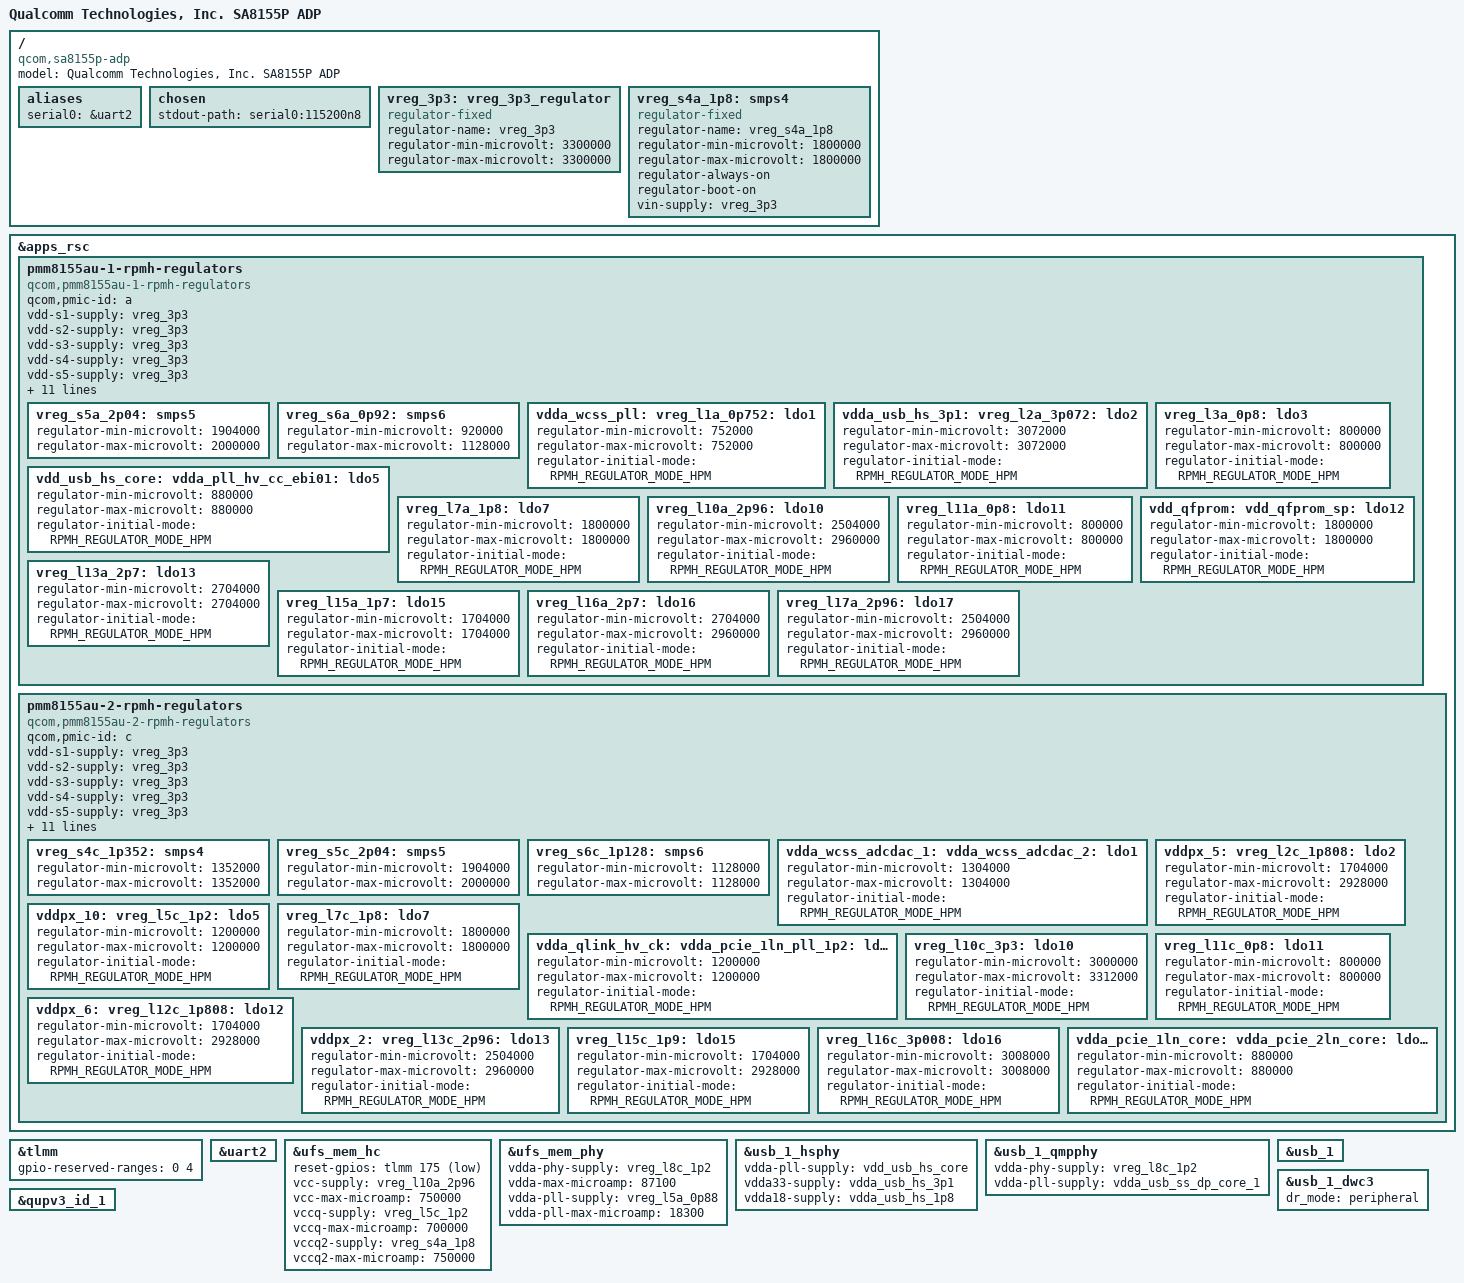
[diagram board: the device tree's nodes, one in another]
// SPDX-License-Identifier: BSD-3-Clause
/*
 * Copyright (c) 2021, Linaro Limited
 */

/dts-v1/;

#include <dt-bindings/regulator/qcom,rpmh-regulator.h>
#include <dt-bindings/gpio/gpio.h>
#include "sm8150.dtsi"
#include "pmm8155au_1.dtsi"
#include "pmm8155au_2.dtsi"

/ {
	model = "Qualcomm Technologies, Inc. SA8155P ADP";
	compatible = "qcom,sa8155p-adp";

	aliases {
		serial0 = &uart2;
	};

	chosen {
		stdout-path = "serial0:115200n8";
	};

	vreg_3p3: vreg_3p3_regulator {
		compatible = "regulator-fixed";
		regulator-name = "vreg_3p3";
		regulator-min-microvolt = <3300000>;
		regulator-max-microvolt = <3300000>;
	};

	/*
	 * Apparently RPMh does not provide support for PM8150 S4 because it
	 * is always-on; model it as a fixed regulator.
	 */
	vreg_s4a_1p8: smps4 {
		compatible = "regulator-fixed";
		regulator-name = "vreg_s4a_1p8";

		regulator-min-microvolt = <1800000>;
		regulator-max-microvolt = <1800000>;

		regulator-always-on;
		regulator-boot-on;

		vin-supply = <&vreg_3p3>;
	};
};

&apps_rsc {
	pmm8155au-1-rpmh-regulators {
		compatible = "qcom,pmm8155au-1-rpmh-regulators";
		qcom,pmic-id = "a";

		vdd-s1-supply = <&vreg_3p3>;
		vdd-s2-supply = <&vreg_3p3>;
		vdd-s3-supply = <&vreg_3p3>;
		vdd-s4-supply = <&vreg_3p3>;
		vdd-s5-supply = <&vreg_3p3>;
		vdd-s6-supply = <&vreg_3p3>;
		vdd-s7-supply = <&vreg_3p3>;
		vdd-s8-supply = <&vreg_3p3>;
		vdd-s9-supply = <&vreg_3p3>;
		vdd-s10-supply = <&vreg_3p3>;

		vdd-l1-l8-l11-supply = <&vreg_s6a_0p92>;
		vdd-l2-l10-supply = <&vreg_3p3>;
		vdd-l3-l4-l5-l18-supply = <&vreg_s6a_0p92>;
		vdd-l6-l9-supply = <&vreg_s6a_0p92>;
		vdd-l7-l12-l14-l15-supply = <&vreg_s5a_2p04>;
		vdd-l13-l16-l17-supply = <&vreg_3p3>;

		vreg_s5a_2p04: smps5 {
			regulator-min-microvolt = <1904000>;
			regulator-max-microvolt = <2000000>;
		};

		vreg_s6a_0p92: smps6 {
			regulator-min-microvolt = <920000>;
			regulator-max-microvolt = <1128000>;
		};

		vdda_wcss_pll:
		vreg_l1a_0p752: ldo1 {
			regulator-min-microvolt = <752000>;
			regulator-max-microvolt = <752000>;
			regulator-initial-mode = <RPMH_REGULATOR_MODE_HPM>;
		};

		vdda_usb_hs_3p1:
		vreg_l2a_3p072: ldo2 {
			regulator-min-microvolt = <3072000>;
			regulator-max-microvolt = <3072000>;
			regulator-initial-mode = <RPMH_REGULATOR_MODE_HPM>;
		};

		vreg_l3a_0p8: ldo3 {
			regulator-min-microvolt = <800000>;
			regulator-max-microvolt = <800000>;
			regulator-initial-mode = <RPMH_REGULATOR_MODE_HPM>;
		};

		vdd_usb_hs_core:
		vdda_pll_hv_cc_ebi01:
		vdda_pll_hv_cc_ebi23:
		vdda_ufs_2ln_core:
		vdda_ufs_2ln_core:
		vdda_usb_ss_core:
		vdda_usb_ss_dp_core_1:
		vdda_usb_ss_dp_core_2:
		vdda_sp_sensor:
		vdda_qlink_lv:
		vdda_qlink_lv_ck:
		vdda_qrefs_0p875_5:
		vreg_l5a_0p88: ldo5 {
			regulator-min-microvolt = <880000>;
			regulator-max-microvolt = <880000>;
			regulator-initial-mode = <RPMH_REGULATOR_MODE_HPM>;
		};

		vreg_l7a_1p8: ldo7 {
			regulator-min-microvolt = <1800000>;
			regulator-max-microvolt = <1800000>;
			regulator-initial-mode = <RPMH_REGULATOR_MODE_HPM>;
		};

		vreg_l10a_2p96: ldo10 {
			regulator-min-microvolt = <2504000>;
			regulator-max-microvolt = <2960000>;
			regulator-initial-mode = <RPMH_REGULATOR_MODE_HPM>;
		};

		vreg_l11a_0p8: ldo11 {
			regulator-min-microvolt = <800000>;
			regulator-max-microvolt = <800000>;
			regulator-initial-mode = <RPMH_REGULATOR_MODE_HPM>;
		};

		vdd_qfprom:
		vdd_qfprom_sp:
		vdda_usb_hs_1p8:
		vdda_apc_cs_1p8:
		vdda_gfx_cs_1p8:
		vddpx_11:
		vreg_l12a_1p8: ldo12 {
			regulator-min-microvolt = <1800000>;
			regulator-max-microvolt = <1800000>;
			regulator-initial-mode = <RPMH_REGULATOR_MODE_HPM>;
		};

		vreg_l13a_2p7: ldo13 {
			regulator-min-microvolt = <2704000>;
			regulator-max-microvolt = <2704000>;
			regulator-initial-mode = <RPMH_REGULATOR_MODE_HPM>;
		};

		vreg_l15a_1p7: ldo15 {
			regulator-min-microvolt = <1704000>;
			regulator-max-microvolt = <1704000>;
			regulator-initial-mode = <RPMH_REGULATOR_MODE_HPM>;
		};

		vreg_l16a_2p7: ldo16 {
			regulator-min-microvolt = <2704000>;
			regulator-max-microvolt = <2960000>;
			regulator-initial-mode = <RPMH_REGULATOR_MODE_HPM>;
		};

		vreg_l17a_2p96: ldo17 {
			regulator-min-microvolt = <2504000>;
			regulator-max-microvolt = <2960000>;
			regulator-initial-mode = <RPMH_REGULATOR_MODE_HPM>;
		};
	};

	pmm8155au-2-rpmh-regulators {
		compatible = "qcom,pmm8155au-2-rpmh-regulators";
		qcom,pmic-id = "c";

		vdd-s1-supply = <&vreg_3p3>;
		vdd-s2-supply = <&vreg_3p3>;
		vdd-s3-supply = <&vreg_3p3>;
		vdd-s4-supply = <&vreg_3p3>;
		vdd-s5-supply = <&vreg_3p3>;
		vdd-s6-supply = <&vreg_3p3>;
		vdd-s7-supply = <&vreg_3p3>;
		vdd-s8-supply = <&vreg_3p3>;
		vdd-s9-supply = <&vreg_3p3>;
		vdd-s10-supply = <&vreg_3p3>;

		vdd-l1-l8-l11-supply = <&vreg_s4c_1p352>;
		vdd-l2-l10-supply = <&vreg_3p3>;
		vdd-l3-l4-l5-l18-supply = <&vreg_s4c_1p352>;
		vdd-l6-l9-supply = <&vreg_s6c_1p128>;
		vdd-l7-l12-l14-l15-supply = <&vreg_s5c_2p04>;
		vdd-l13-l16-l17-supply = <&vreg_3p3>;

		vreg_s4c_1p352: smps4 {
			regulator-min-microvolt = <1352000>;
			regulator-max-microvolt = <1352000>;
		};

		vreg_s5c_2p04: smps5 {
			regulator-min-microvolt = <1904000>;
			regulator-max-microvolt = <2000000>;
		};

		vreg_s6c_1p128: smps6 {
			regulator-min-microvolt = <1128000>;
			regulator-max-microvolt = <1128000>;
		};

		vdda_wcss_adcdac_1:
		vdda_wcss_adcdac_2:
		vreg_l1c_1p304: ldo1 {
			regulator-min-microvolt = <1304000>;
			regulator-max-microvolt = <1304000>;
			regulator-initial-mode = <RPMH_REGULATOR_MODE_HPM>;
		};

		vddpx_5:
		vreg_l2c_1p808: ldo2 {
			regulator-min-microvolt = <1704000>;
			regulator-max-microvolt = <2928000>;
			regulator-initial-mode = <RPMH_REGULATOR_MODE_HPM>;
		};

		vddpx_10:
		vreg_l5c_1p2: ldo5 {
			regulator-min-microvolt = <1200000>;
			regulator-max-microvolt = <1200000>;
			regulator-initial-mode = <RPMH_REGULATOR_MODE_HPM>;
		};

		vreg_l7c_1p8: ldo7 {
			regulator-min-microvolt = <1800000>;
			regulator-max-microvolt = <1800000>;
			regulator-initial-mode = <RPMH_REGULATOR_MODE_HPM>;
		};

		vdda_qlink_hv_ck:
		vdda_pcie_1ln_pll_1p2:
		vdda_pcie_2ln_pll_1p2:
		vdda_hv_refgen0:
		vdda_ufs_2ln_1p2:
		vdda_usb_ss_1p2:
		vdda_usb_ss_dp_1p2:
		vdda_csi_1p2:
		vdda_dsi_1p2:
		vreg_l8c_1p2: ldo8 {
			regulator-min-microvolt = <1200000>;
			regulator-max-microvolt = <1200000>;
			regulator-initial-mode = <RPMH_REGULATOR_MODE_HPM>;
		};

		vreg_l10c_3p3: ldo10 {
			regulator-min-microvolt = <3000000>;
			regulator-max-microvolt = <3312000>;
			regulator-initial-mode = <RPMH_REGULATOR_MODE_HPM>;
		};

		vreg_l11c_0p8: ldo11 {
			regulator-min-microvolt = <800000>;
			regulator-max-microvolt = <800000>;
			regulator-initial-mode = <RPMH_REGULATOR_MODE_HPM>;
		};

		vddpx_6:
		vreg_l12c_1p808: ldo12 {
			regulator-min-microvolt = <1704000>;
			regulator-max-microvolt = <2928000>;
			regulator-initial-mode = <RPMH_REGULATOR_MODE_HPM>;
		};

		vddpx_2:
		vreg_l13c_2p96: ldo13 {
			regulator-min-microvolt = <2504000>;
			regulator-max-microvolt = <2960000>;
			regulator-initial-mode = <RPMH_REGULATOR_MODE_HPM>;
		};

		vreg_l15c_1p9: ldo15 {
			regulator-min-microvolt = <1704000>;
			regulator-max-microvolt = <2928000>;
			regulator-initial-mode = <RPMH_REGULATOR_MODE_HPM>;
		};

		vreg_l16c_3p008: ldo16 {
			regulator-min-microvolt = <3008000>;
			regulator-max-microvolt = <3008000>;
			regulator-initial-mode = <RPMH_REGULATOR_MODE_HPM>;
		};

		vdda_pcie_1ln_core:
		vdda_pcie_2ln_core:
		vdda_csi_0_0p9:
		vdda_csi_1_0p9:
		vdda_csi_2_0p9:
		vdda_csi_3_0p9:
		vreg_l18c_0p88: ldo18 {
			regulator-min-microvolt = <880000>;
			regulator-max-microvolt = <880000>;
			regulator-initial-mode = <RPMH_REGULATOR_MODE_HPM>;
		};
	};
};

&tlmm {
	gpio-reserved-ranges = <0 4>;
};

&uart2 {
	status = "okay";
};

&ufs_mem_hc {
	status = "okay";

	reset-gpios = <&tlmm 175 GPIO_ACTIVE_LOW>;

	vcc-supply = <&vreg_l10a_2p96>;
	vcc-max-microamp = <750000>;
	vccq-supply = <&vreg_l5c_1p2>;
	vccq-max-microamp = <700000>;
	vccq2-supply = <&vreg_s4a_1p8>;
	vccq2-max-microamp = <750000>;
};

&ufs_mem_phy {
	status = "okay";

	vdda-phy-supply = <&vreg_l8c_1p2>;
	vdda-max-microamp = <87100>;
	vdda-pll-supply = <&vreg_l5a_0p88>;
	vdda-pll-max-microamp = <18300>;
};


&usb_1_hsphy {
	status = "okay";
	vdda-pll-supply = <&vdd_usb_hs_core>;
	vdda33-supply = <&vdda_usb_hs_3p1>;
	vdda18-supply = <&vdda_usb_hs_1p8>;
};

&usb_1_qmpphy {
	status = "okay";
	vdda-phy-supply = <&vreg_l8c_1p2>;
	vdda-pll-supply = <&vdda_usb_ss_dp_core_1>;
};

&usb_1 {
	status = "okay";
};

&usb_1_dwc3 {
	dr_mode = "peripheral";
};

&qupv3_id_1 {
	status = "okay";
};
